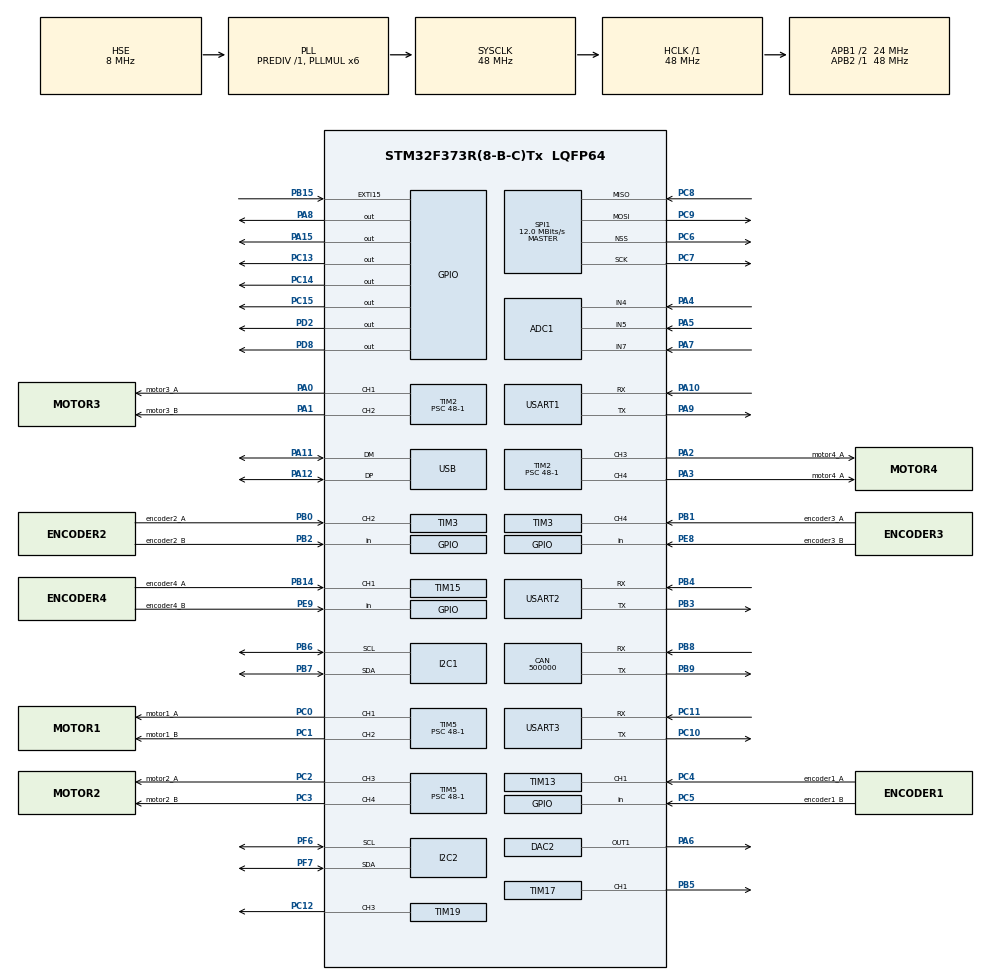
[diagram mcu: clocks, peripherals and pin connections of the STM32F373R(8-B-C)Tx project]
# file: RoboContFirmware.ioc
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ADC1.Channel-0\#ChannelRegularConversion=ADC_CHANNEL_4
ADC1.NbrOfConversionFlag=1
ADC1.Rank-0\#ChannelRegularConversion=1
ADC1.SamplingTime-0\#ChannelRegularConversion=ADC_SAMPLETIME_1CYCLE_5
ADC1.master=1
CAN.CalculateBaudRate=500000
CAN.CalculateTimeBit=2000
CAN.CalculateTimeQuantum=666.6666666666666
I2C1.Timing=0x00201D2B
I2C2.Timing=0x00201D2B
Mcu.Family=STM32F3
Mcu.Name=STM32F373R(8-B-C)Tx
Mcu.Package=LQFP64
NVIC.PriorityGroup=NVIC_PRIORITYGROUP_4
PA0.GPIO_Label=motor3_A
PA0.Signal=S_TIM2_CH1_ETR
PA1.GPIO_Label=motor3_B
PA1.Signal=S_TIM2_CH2
PA10.Mode=Asynchronous
PA10.Signal=USART1_RX
PA11.Mode=Device
PA11.Signal=USB_DM
PA12.Mode=Device
PA12.Signal=USB_DP
PA13.Mode=Serial_Wire
PA13.Signal=SYS_JTMS-SWDIO
PA14.Mode=Serial_Wire
PA14.Signal=SYS_JTCK-SWCLK
PA15.Signal=GPIO_Output
PA2.GPIO_Label=motor4_A
PA2.Signal=S_TIM2_CH3
PA3.GPIO_Label=motor4_A
PA3.Signal=S_TIM2_CH4
PA4.Signal=SharedAnalog_PA4
PA5.Signal=SharedAnalog_PA5
PA6.Signal=SharedAnalog_PA6
PA7.Mode=IN7
PA7.Signal=ADC1_IN7
PA8.Signal=GPIO_Output
PA9.Mode=Asynchronous
PA9.Signal=USART1_TX
PB0.GPIO_Label=encoder2_A
PB0.Signal=S_TIM3_CH2
PB1.GPIO_Label=encoder3_A
PB1.Signal=S_TIM3_CH4
PB14.GPIO_Label=encoder4_A
PB14.Signal=S_TIM15_CH1
PB15.Signal=GPXTI15
PB2.GPIO_Label=encoder2_B
PB2.Signal=GPIO_Input
PB3.Mode=Asynchronous
PB3.Signal=USART2_TX
PB4.Mode=Asynchronous
PB4.Signal=USART2_RX
PB5.Signal=S_TIM17_CH1
PB6.Mode=I2C
PB6.Signal=I2C1_SCL
PB7.Mode=I2C
PB7.Signal=I2C1_SDA
PB8.Mode=CAN_Activate
PB8.Signal=CAN_RX
PB9.Mode=CAN_Activate
PB9.Signal=CAN_TX
PC0.GPIO_Label=motor1_A
PC0.Signal=S_TIM5_CH1_ETR
PC1.GPIO_Label=motor1_B
PC1.Signal=S_TIM5_CH2
PC10.Mode=Asynchronous
PC10.Signal=USART3_TX
PC11.Mode=Asynchronous
PC11.Signal=USART3_RX
PC12.Signal=S_TIM19_CH3
PC13.Signal=GPIO_Output
PC14-OSC32_IN.Signal=GPIO_Output
PC15-OSC32_OUT.Signal=GPIO_Output
PC2.GPIO_Label=motor2_A
PC2.Signal=S_TIM5_CH3
PC3.GPIO_Label=motor2_B
PC3.Signal=S_TIM5_CH4
PC4.GPIO_Label=encoder1_A
PC4.Signal=S_TIM13_CH1
PC5.GPIO_Label=encoder1_B
PC5.Signal=GPIO_Input
PC6.Mode=NSS_Signal_Hard_Output
PC6.Signal=SPI1_NSS
PC7.Mode=Full_Duplex_Master
PC7.Signal=SPI1_SCK
PC8.Mode=Full_Duplex_Master
PC8.Signal=SPI1_MISO
PC9.Mode=Full_Duplex_Master
PC9.Signal=SPI1_MOSI
PD2.Signal=GPIO_Output
PD8.Signal=GPIO_Output
PE8.GPIO_Label=encoder3_B
PE8.Signal=GPIO_Input
PE9.GPIO_Label=encoder4_B
PE9.Signal=GPIO_Input
PF0-OSC_IN.Mode=HSE-External-Oscillator
PF0-OSC_IN.Signal=RCC_OSC_IN
PF1-OSC_OUT.Mode=HSE-External-Oscillator
PF1-OSC_OUT.Signal=RCC_OSC_OUT
PF6.Mode=I2C
PF6.Signal=I2C2_SCL
PF7.Mode=I2C
PF7.Signal=I2C2_SDA
ProjectManager.HeapSize=0x200
ProjectManager.StackSize=0x400
ProjectManager.TargetToolchain=STM32CubeIDE
RCC.AHBFreq_Value=48000000
RCC.APB1CLKDivider=RCC_HCLK_DIV2
RCC.APB1Freq_Value=24000000
RCC.APB1TimFreq_Value=48000000
RCC.APB2Freq_Value=48000000
RCC.APB2TimFreq_Value=48000000
RCC.CortexFreq_Value=48000000
RCC.HCLKFreq_Value=48000000
RCC.HSE_VALUE=8000000
RCC.HSI_VALUE=8000000
RCC.LSE_VALUE=32768
RCC.PLLMUL=RCC_PLL_MUL6
RCC.SYSCLKFreq_VALUE=48000000
RCC.SYSCLKSource=RCC_SYSCLKSOURCE_PLLCLK
RCC.USBFreq_Value=48000000
SH.S_TIM13_CH1.0=TIM13_CH1,Input_Capture1_from_TI1
SH.S_TIM15_CH1.0=TIM15_CH1,Input_Capture1_from_TI1
SH.S_TIM17_CH1.0=TIM17_CH1,PWM Generation1 CH1
SH.S_TIM19_CH3.0=TIM19_CH3,PWM Generation3 CH3
SH.S_TIM2_CH1_ETR.0=TIM2_CH1,PWM Generation1 CH1
SH.S_TIM2_CH2.0=TIM2_CH2,PWM Generation2 CH2
SH.S_TIM2_CH3.0=TIM2_CH3,PWM Generation3 CH3
SH.S_TIM2_CH4.0=TIM2_CH4,PWM Generation4 CH4
SH.S_TIM3_CH2.0=TIM3_CH2,Input_Capture2_from_TI2
SH.S_TIM3_CH4.0=TIM3_CH4,Input_Capture4_from_TI4
SH.S_TIM5_CH1_ETR.0=TIM5_CH1,PWM Generation1 CH1
SH.S_TIM5_CH2.0=TIM5_CH2,PWM Generation2 CH2
SH.S_TIM5_CH3.0=TIM5_CH3,PWM Generation3 CH3
SH.S_TIM5_CH4.0=TIM5_CH4,PWM Generation4 CH4
SH.SharedAnalog_PA4.0=ADC1_IN4,IN4
SH.SharedAnalog_PA4.1=DAC1_OUT1,DAC_OUT1
SH.SharedAnalog_PA5.0=ADC1_IN5,IN5
SH.SharedAnalog_PA5.1=DAC1_OUT2,Enable_DAC_OUT2
SH.SharedAnalog_PA6.0=DAC2_OUT1,DAC_OUT1
SH.SharedAnalog_PA6.1=ADC1_IN6,IN6
SPI1.BaudRatePrescaler=SPI_BAUDRATEPRESCALER_4
SPI1.CalculateBaudRate=12.0 MBits/s
SPI1.Direction=SPI_DIRECTION_2LINES
SPI1.Mode=SPI_MODE_MASTER
SPI1.VirtualNSS=VM_NSSHARD
SPI1.VirtualType=VM_MASTER
TIM13.Channel=TIM_CHANNEL_1
TIM15.Channel-Input_Capture1_from_TI1=TIM_CHANNEL_1
TIM17.Channel=TIM_CHANNEL_1
TIM19.Channel-PWM\ Generation3\ CH3=TIM_CHANNEL_3
TIM2.Channel-PWM\ Generation1\ CH1=TIM_CHANNEL_1
TIM2.Channel-PWM\ Generation2\ CH2=TIM_CHANNEL_2
TIM2.Channel-PWM\ Generation3\ CH3=TIM_CHANNEL_3
TIM2.Channel-PWM\ Generation4\ CH4=TIM_CHANNEL_4
TIM2.Period=1000-1
TIM2.Prescaler=48-1
TIM3.Channel-Input_Capture2_from_TI2=TIM_CHANNEL_2
TIM3.Channel-Input_Capture4_from_TI4=TIM_CHANNEL_4
TIM5.Channel-PWM\ Generation1\ CH1=TIM_CHANNEL_1
TIM5.Channel-PWM\ Generation2\ CH2=TIM_CHANNEL_2
TIM5.Channel-PWM\ Generation3\ CH3=TIM_CHANNEL_3
TIM5.Channel-PWM\ Generation4\ CH4=TIM_CHANNEL_4
TIM5.Period=1000-1
TIM5.Prescaler=48-1
USART1.VirtualMode-Asynchronous=VM_ASYNC
USART2.VirtualMode-Asynchronous=VM_ASYNC
USART3.VirtualMode-Asynchronous=VM_ASYNC
VP_TIM13_VS_ClockSourceINT.Mode=Enable_Timer
VP_TIM15_VS_ClockSourceINT.Mode=Internal
VP_TIM17_VS_ClockSourceINT.Mode=Enable_Timer
VP_TIM2_VS_ClockSourceINT.Mode=Internal
VP_TIM5_VS_ClockSourceINT.Mode=Internal
board=custom

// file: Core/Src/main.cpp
/* USER CODE BEGIN Header */
/**
  ******************************************************************************
  * @file           : main.c
  * @brief          : Main program body
  ******************************************************************************
  * @attention
  *
  * Copyright (c) 2025 STMicroelectronics.
  * All rights reserved.
  *
  * This software is licensed under terms that can be found in the LICENSE file
  * in the root directory of this software component.
  * If no LICENSE file comes with this software, it is provided AS-IS.
  *
  ******************************************************************************
  */
/* USER CODE END Header */
#include "main.h"
#include "adc.h"
#include "can.h"
#include "dac.h"
#include "i2c.h"
#include "spi.h"
#include "tim.h"
#include "usart.h"
#include "usb.h"
#include "gpio.h"

#include <RoboContFirmware/Debug/test.hpp>

void SystemClock_Config(void);

int main(void)
{

  /* MCU Configuration--------------------------------------------------------*/

  /* Reset of all peripherals, Initializes the Flash interface and the Systick. */
  HAL_Init();

  /* Configure the system clock */
  SystemClock_Config();

  /* Initialize all configured peripherals */
  MX_GPIO_Init();
  MX_ADC1_Init();
  MX_CAN_Init();
  MX_DAC1_Init();
  MX_DAC2_Init();
  MX_TIM2_Init();
  MX_TIM3_Init();
  MX_TIM5_Init();
  MX_TIM13_Init();
  MX_USB_PCD_Init();
  MX_TIM15_Init();
  MX_I2C1_Init();
  MX_I2C2_Init();
  MX_SPI1_Init();
  MX_USART1_UART_Init();
  MX_TIM17_Init();
  MX_TIM19_Init();
  MX_USART2_UART_Init();
  MX_USART3_UART_Init();
  /* USER CODE BEGIN 2 */

  test();
  /* USER CODE END 2 */

  /* Infinite loop */
  while (1)
  {

  }
}

void SystemClock_Config(void)
{
  RCC_OscInitTypeDef RCC_OscInitStruct = {0};
  RCC_ClkInitTypeDef RCC_ClkInitStruct = {0};
  RCC_PeriphCLKInitTypeDef PeriphClkInit = {0};

  /** Initializes the RCC Oscillators according to the specified parameters
  * in the RCC_OscInitTypeDef structure.
  */
  RCC_OscInitStruct.OscillatorType = RCC_OSCILLATORTYPE_HSI|RCC_OSCILLATORTYPE_HSE;
  RCC_OscInitStruct.HSEState = RCC_HSE_ON;
  RCC_OscInitStruct.HSEPredivValue = RCC_HSE_PREDIV_DIV1;
  RCC_OscInitStruct.HSIState = RCC_HSI_ON;
  RCC_OscInitStruct.HSICalibrationValue = RCC_HSICALIBRATION_DEFAULT;
  RCC_OscInitStruct.PLL.PLLState = RCC_PLL_ON;
  RCC_OscInitStruct.PLL.PLLSource = RCC_PLLSOURCE_HSE;
  RCC_OscInitStruct.PLL.PLLMUL = RCC_PLL_MUL6;
  if (HAL_RCC_OscConfig(&RCC_OscInitStruct) != HAL_OK)
  {
    Error_Handler();
  }

  /** Initializes the CPU, AHB and APB buses clocks
  */
  RCC_ClkInitStruct.ClockType = RCC_CLOCKTYPE_HCLK|RCC_CLOCKTYPE_SYSCLK
                              |RCC_CLOCKTYPE_PCLK1|RCC_CLOCKTYPE_PCLK2;
  RCC_ClkInitStruct.SYSCLKSource = RCC_SYSCLKSOURCE_PLLCLK;
  RCC_ClkInitStruct.AHBCLKDivider = RCC_SYSCLK_DIV1;
  RCC_ClkInitStruct.APB1CLKDivider = RCC_HCLK_DIV2;
  RCC_ClkInitStruct.APB2CLKDivider = RCC_HCLK_DIV1;

  if (HAL_RCC_ClockConfig(&RCC_ClkInitStruct, FLASH_LATENCY_1) != HAL_OK)
  {
    Error_Handler();
  }
  PeriphClkInit.PeriphClockSelection = RCC_PERIPHCLK_USB|RCC_PERIPHCLK_USART1
                              |RCC_PERIPHCLK_USART2|RCC_PERIPHCLK_USART3
                              |RCC_PERIPHCLK_I2C1|RCC_PERIPHCLK_I2C2
                              |RCC_PERIPHCLK_ADC1;
  PeriphClkInit.Usart1ClockSelection = RCC_USART1CLKSOURCE_PCLK2;
  PeriphClkInit.Usart2ClockSelection = RCC_USART2CLKSOURCE_PCLK1;
  PeriphClkInit.Usart3ClockSelection = RCC_USART3CLKSOURCE_PCLK1;
  PeriphClkInit.I2c1ClockSelection = RCC_I2C1CLKSOURCE_HSI;
  PeriphClkInit.I2c2ClockSelection = RCC_I2C2CLKSOURCE_HSI;
  PeriphClkInit.USBClockSelection = RCC_USBCLKSOURCE_PLL;
  PeriphClkInit.Adc1ClockSelection = RCC_ADC1PCLK2_DIV2;

  if (HAL_RCCEx_PeriphCLKConfig(&PeriphClkInit) != HAL_OK)
  {
    Error_Handler();
  }
}

void Error_Handler(void)
{
  __disable_irq();
  while (1)
  {
  }
}
